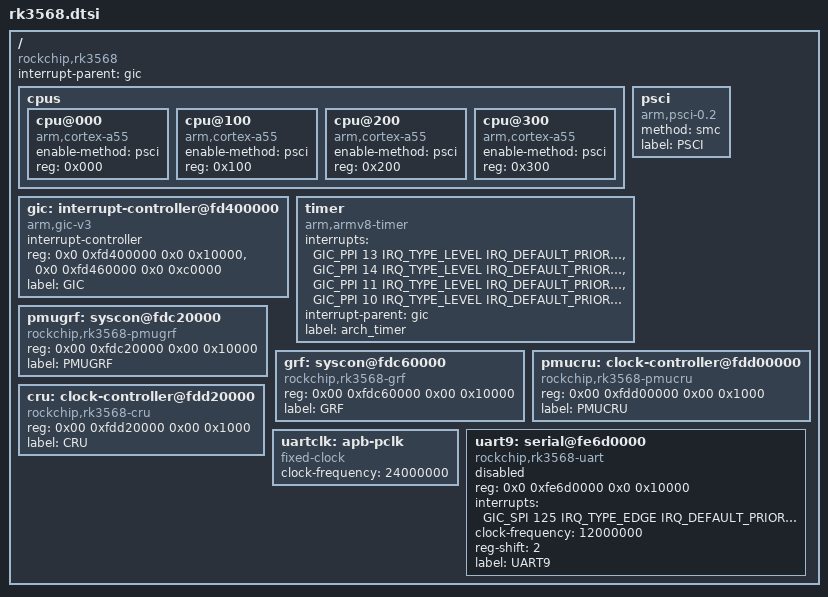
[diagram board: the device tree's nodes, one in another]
/*
 * Copyright 2020 NXP
 * Copyright 2022 HNU-ESNL
 * Copyright 2022 openEuler SIG-Zephyr
 *
 * SPDX-License-Identifier: Apache-2.0
 */

#include <mem.h>
#include <arm64/armv8-a.dtsi>
#include <dt-bindings/interrupt-controller/arm-gic.h>

/ {
	#address-cells = <2>;
	#size-cells = <2>;

	compatible = "rockchip,rk3568";
	interrupt-parent = <&gic>;

	cpus {
		#address-cells = <1>;
		#size-cells = <0>;

		cpu@000 {
			device_type = "cpu";
			compatible = "arm,cortex-a55";
			enable-method = "psci";
			reg = <0x000>;
		};

		cpu@100 {
			device_type = "cpu";
			compatible = "arm,cortex-a55";
			enable-method = "psci";
			reg = <0x100>;
		};

		cpu@200 {
			device_type = "cpu";
			compatible = "arm,cortex-a55";
			enable-method = "psci";
			reg = <0x200>;

		};

		cpu@300 {
			device_type = "cpu";
			compatible = "arm,cortex-a55";
			enable-method = "psci";
			reg = <0x300>;
		};
	};

	gic: interrupt-controller@fd400000 {
		#address-cells = <1>;
		compatible = "arm,gic-v3","arm,gic";
		#interrupt-cells = <4>;
		interrupt-controller;

		reg = <0x0 0xfd400000 0x0 0x10000>, /* GICD */
		      <0x0 0xfd460000 0x0 0xc0000>; /* GICR */
		status = "okay";
		label = "GIC";
	};

	psci {
		compatible = "arm,psci-0.2", "arm,psci";
		method = "smc";
		label = "PSCI";
	};

	timer {
		compatible = "arm,armv8-timer";
		interrupts = <GIC_PPI 13 IRQ_TYPE_LEVEL IRQ_DEFAULT_PRIORITY>,
			     <GIC_PPI 14 IRQ_TYPE_LEVEL IRQ_DEFAULT_PRIORITY>,
			     <GIC_PPI 11 IRQ_TYPE_LEVEL IRQ_DEFAULT_PRIORITY>,
			     <GIC_PPI 10 IRQ_TYPE_LEVEL IRQ_DEFAULT_PRIORITY>;
		interrupt-parent = <&gic>;
		label = "arch_timer";
	};

	pmugrf: syscon@fdc20000 {
		compatible = "rockchip,rk3568-pmugrf","syscon", "simple-mfd";
		reg = <0x00 0xfdc20000 0x00 0x10000>;
		label = "PMUGRF";
		status = "okay";
	};

	grf: syscon@fdc60000 {
		compatible = "rockchip,rk3568-grf","syscon","simple-mfd";
		reg = <0x00 0xfdc60000 0x00 0x10000>;
		label = "GRF";
		status = "okay";
	};

	pmucru: clock-controller@fdd00000 {
		compatible = "rockchip,rk3568-pmucru";
		reg = <0x00 0xfdd00000 0x00 0x1000>;
		#clock-cells = <0x01>;
		#reset-cells = <0x01>;
		status = "okay";
		label = "PMUCRU";
	};

	cru: clock-controller@fdd20000 {
		compatible = "rockchip,rk3568-cru";
		reg = <0x00 0xfdd20000 0x00 0x1000>;
		#clock-cells = <0x01>;
		#reset-cells = <0x01>;
		status = "okay";
		label = "CRU";
	};

	uartclk: apb-pclk {
		compatible = "fixed-clock";
		clock-frequency = <24000000>;
		#clock-cells = <0>;
	};

	uart9: serial@fe6d0000 {
		compatible = "rockchip,rk3568-uart", "ns16550";
		reg = <0x0 0xfe6d0000 0x0 0x10000>;
		interrupts = <GIC_SPI 125 IRQ_TYPE_EDGE IRQ_DEFAULT_PRIORITY>;
		clock-frequency = <12000000>;
		reg-shift = <2>;
		status = "disabled";
		label = "UART9";
	};

};
